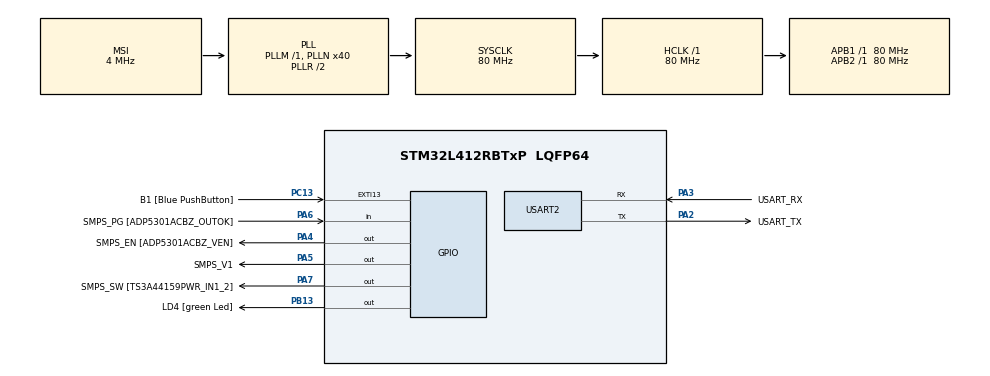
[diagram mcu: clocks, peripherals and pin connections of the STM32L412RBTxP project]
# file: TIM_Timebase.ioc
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Mcu.Family=STM32L4
Mcu.Name=STM32L412RBTxP
Mcu.Package=LQFP64
NVIC.PriorityGroup=NVIC_PRIORITYGROUP_4
NVIC.TIM2_IRQn=true\:0\:0\:false\:false\:true\:true\:true
PA13\ (JTMS/SWDIO).GPIO_Label=TMS
PA13\ (JTMS/SWDIO).Mode=Serial_Wire
PA13\ (JTMS/SWDIO).Signal=SYS_JTMS-SWDIO
PA14\ (JTCK/SWCLK).GPIO_Label=TCK
PA14\ (JTCK/SWCLK).Mode=Serial_Wire
PA14\ (JTCK/SWCLK).Signal=SYS_JTCK-SWCLK
PA2.GPIO_Label=USART_TX
PA2.GPIO_PuPd=GPIO_NOPULL
PA2.GPIO_Speed=GPIO_SPEED_FREQ_VERY_HIGH
PA2.Mode=Asynchronous
PA2.Signal=USART2_TX
PA3.GPIO_Label=USART_RX
PA3.GPIO_PuPd=GPIO_NOPULL
PA3.GPIO_Speed=GPIO_SPEED_FREQ_VERY_HIGH
PA3.Mode=Asynchronous
PA3.Signal=USART2_RX
PA4.GPIO_Label=SMPS_EN [ADP5301ACBZ_VEN]
PA4.Signal=GPIO_Output
PA5.GPIO_Label=SMPS_V1
PA5.GPIO_ModeDefaultOutputPP=GPIO_MODE_OUTPUT_PP
PA5.GPIO_PuPd=GPIO_NOPULL
PA5.GPIO_Speed=GPIO_SPEED_FREQ_LOW
PA5.Signal=GPIO_Output
PA6.GPIO_Label=SMPS_PG [ADP5301ACBZ_OUTOK]
PA6.GPIO_PuPd=GPIO_PULLUP
PA6.Signal=GPIO_Input
PA7.GPIO_Label=SMPS_SW [TS3A44159PWR_IN1_2]
PA7.Signal=GPIO_Output
PB13.GPIO_Label=LD4 [green Led]
PB13.Signal=GPIO_Output
PB3\ (JTDO/TRACESWO).GPIO_Label=SWO
PB3\ (JTDO/TRACESWO).Signal=SYS_JTDO-SWO
PC13.GPIO_Label=B1 [Blue PushButton]
PC13.GPIO_ModeDefaultEXTI=GPIO_MODE_IT_FALLING
PC13.GPIO_PuPd=GPIO_NOPULL
PC13.Signal=GPXTI13
PC14-OSC32_IN\ (PC14).Signal=RCC_OSC32_IN
PC15-OSC32_OUT\ (PC15).Signal=RCC_OSC32_OUT
PH0-OSC_IN\ (PH0).GPIO_Label=MCO
PH0-OSC_IN\ (PH0).Signal=RCC_OSC_IN
PH1-OSC_OUT\ (PH1).Signal=RCC_OSC_OUT
ProjectManager.HeapSize=0x200
ProjectManager.StackSize=0x400
ProjectManager.TargetToolchain=STM32CubeIDE
RCC.ADCFreq_Value=80000000
RCC.AHBFreq_Value=80000000
RCC.APB1Freq_Value=80000000
RCC.APB1TimFreq_Value=80000000
RCC.APB2Freq_Value=80000000
RCC.APB2TimFreq_Value=80000000
RCC.CortexFreq_Value=80000000
RCC.FLatency=FLASH_LATENCY_4
RCC.HCLKFreq_Value=80000000
RCC.HSE_VALUE=8000000
RCC.HSI48_VALUE=48000000
RCC.HSICalibrationValue=16
RCC.HSI_VALUE=16000000
RCC.MSIAutoCalibration=DISABLED
RCC.MSI_VALUE=4000000
RCC.PLLN=40
RCC.PREFETCH_ENABLE=1
RCC.SYSCLKFreq_VALUE=80000000
RCC.SYSCLKSource=RCC_SYSCLKSOURCE_PLLCLK
RCC.USBFreq_Value=4000000
RCC.VCOOutputFreq_Value=160000000
TIM2.AutoReloadPreload=TIM_AUTORELOAD_PRELOAD_ENABLE
TIM2.Period=999
TIM2.Prescaler=79
USART2.VirtualMode-Asynchronous=VM_ASYNC
VP_TIM2_VS_ClockSourceINT.Mode=Internal
board=NUCLEO-L412RB-P

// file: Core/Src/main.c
/* USER CODE BEGIN Header */
/**
  ******************************************************************************
  * @file           : main.c
  * @brief          : Main program body
  ******************************************************************************
  * @attention
  *
  * <h2><center>&copy; Copyright (c) 2021 STMicroelectronics.
  * All rights reserved.</center></h2>
  *
  * This software component is licensed by ST under BSD 3-Clause license,
  * the "License"; You may not use this file except in compliance with the
  * License. You may obtain a copy of the License at:
  *                        opensource.org/licenses/BSD-3-Clause
  *
  ******************************************************************************
  */
/* USER CODE END Header */
#include "main.h"
#include "tim.h"
#include "usart.h"
#include "gpio.h"

/* USER CODE BEGIN PV */
volatile int gTimerCnt;

/* USER CODE END PV */

void SystemClock_Config(void);

int main(void)
{

  /* MCU Configuration--------------------------------------------------------*/

  /* Reset of all peripherals, Initializes the Flash interface and the Systick. */
  HAL_Init();

  /* Configure the system clock */
  SystemClock_Config();

  /* Initialize all configured peripherals */
  MX_GPIO_Init();
  MX_TIM2_Init();
  MX_USART2_UART_Init();
  /* USER CODE BEGIN 2 */
  if (HAL_TIM_Base_Start_IT (&htim2) != HAL_OK)
  {
	  Error_Handler();
  }
  /* USER CODE END 2 */

  /* Infinite loop */
  while (1)
  {

  }
}

void SystemClock_Config(void)
{
  RCC_OscInitTypeDef RCC_OscInitStruct = {0};
  RCC_ClkInitTypeDef RCC_ClkInitStruct = {0};
  RCC_PeriphCLKInitTypeDef PeriphClkInit = {0};

  /** Configure the main internal regulator output voltage
  */
  if (HAL_PWREx_ControlVoltageScaling(PWR_REGULATOR_VOLTAGE_SCALE1) != HAL_OK)
  {
    Error_Handler();
  }
  /** Initializes the RCC Oscillators according to the specified parameters
  * in the RCC_OscInitTypeDef structure.
  */
  RCC_OscInitStruct.OscillatorType = RCC_OSCILLATORTYPE_MSI;
  RCC_OscInitStruct.MSIState = RCC_MSI_ON;
  RCC_OscInitStruct.MSICalibrationValue = 0;
  RCC_OscInitStruct.MSIClockRange = RCC_MSIRANGE_6;
  RCC_OscInitStruct.PLL.PLLState = RCC_PLL_ON;
  RCC_OscInitStruct.PLL.PLLSource = RCC_PLLSOURCE_MSI;
  RCC_OscInitStruct.PLL.PLLM = 1;
  RCC_OscInitStruct.PLL.PLLN = 40;
  RCC_OscInitStruct.PLL.PLLQ = RCC_PLLQ_DIV2;
  RCC_OscInitStruct.PLL.PLLR = RCC_PLLR_DIV2;
  if (HAL_RCC_OscConfig(&RCC_OscInitStruct) != HAL_OK)
  {
    Error_Handler();
  }
  /** Initializes the CPU, AHB and APB buses clocks
  */
  RCC_ClkInitStruct.ClockType = RCC_CLOCKTYPE_HCLK|RCC_CLOCKTYPE_SYSCLK
                              |RCC_CLOCKTYPE_PCLK1|RCC_CLOCKTYPE_PCLK2;
  RCC_ClkInitStruct.SYSCLKSource = RCC_SYSCLKSOURCE_PLLCLK;
  RCC_ClkInitStruct.AHBCLKDivider = RCC_SYSCLK_DIV1;
  RCC_ClkInitStruct.APB1CLKDivider = RCC_HCLK_DIV1;
  RCC_ClkInitStruct.APB2CLKDivider = RCC_HCLK_DIV1;

  if (HAL_RCC_ClockConfig(&RCC_ClkInitStruct, FLASH_LATENCY_4) != HAL_OK)
  {
    Error_Handler();
  }
  PeriphClkInit.PeriphClockSelection = RCC_PERIPHCLK_USART2;
  PeriphClkInit.Usart2ClockSelection = RCC_USART2CLKSOURCE_PCLK1;
  if (HAL_RCCEx_PeriphCLKConfig(&PeriphClkInit) != HAL_OK)
  {
    Error_Handler();
  }
}

/* USER CODE BEGIN 4 */
void HAL_TIM_PeriodElapsedCallback(TIM_HandleTypeDef *htim)
{
	gTimerCnt++;
	if (gTimerCnt == 1000)
	{
		gTimerCnt = 0;
		HAL_GPIO_TogglePin(LD4_GPIO_Port, LD4_Pin);
	}
}
/* USER CODE END 4 */

void Error_Handler(void)
{
  __disable_irq();
  while (1)
  {
  }
}

/************************ (C) COPYRIGHT STMicroelectronics *****END OF FILE****/
